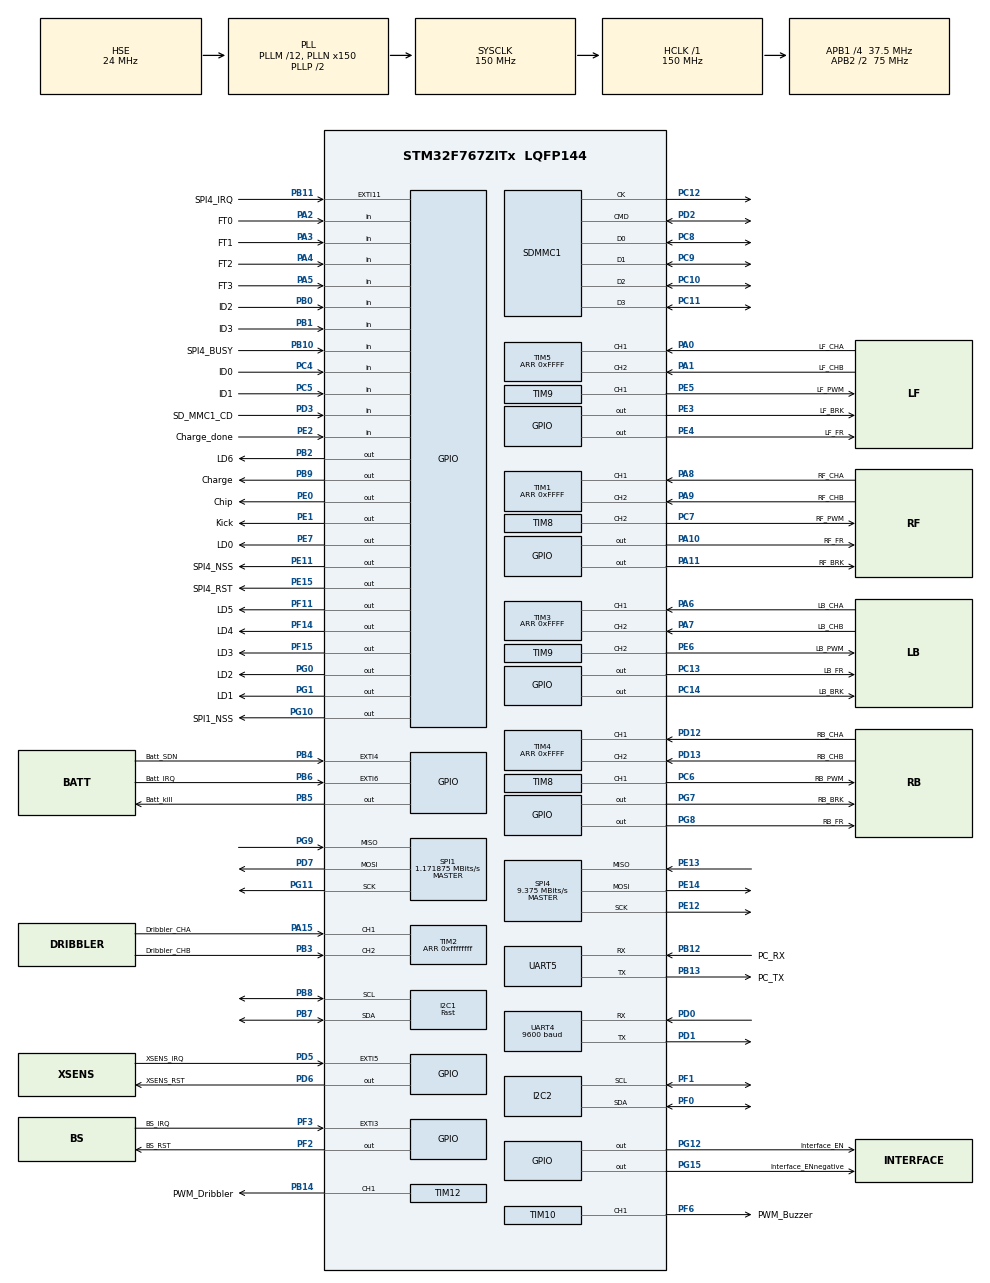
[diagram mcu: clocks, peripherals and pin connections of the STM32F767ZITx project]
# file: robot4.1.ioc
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CORTEX_M7.CPU_DCache=Enabled
CORTEX_M7.CPU_ICache=Enabled
CORTEX_M7.PREFETCH_ENABLE=1
Dma.I2C1_RX.5.Direction=DMA_PERIPH_TO_MEMORY
Dma.I2C1_RX.5.FIFOMode=DMA_FIFOMODE_DISABLE
Dma.I2C1_RX.5.Instance=DMA1_Stream0
Dma.I2C1_RX.5.MemDataAlignment=DMA_MDATAALIGN_BYTE
Dma.I2C1_RX.5.MemInc=DMA_MINC_ENABLE
Dma.I2C1_RX.5.Mode=DMA_NORMAL
Dma.I2C1_RX.5.PeriphDataAlignment=DMA_PDATAALIGN_BYTE
Dma.I2C1_RX.5.PeriphInc=DMA_PINC_DISABLE
Dma.I2C1_RX.5.Priority=DMA_PRIORITY_MEDIUM
Dma.Request0=SPI1_RX
Dma.Request1=SPI4_RX
Dma.Request2=UART5_TX
Dma.Request3=SPI4_TX
Dma.Request4=SPI1_TX
Dma.Request5=I2C1_RX
Dma.Request6=SDMMC1
Dma.SDMMC1.6.Direction=DMA_PERIPH_TO_MEMORY
Dma.SDMMC1.6.FIFOMode=DMA_FIFOMODE_ENABLE
Dma.SDMMC1.6.FIFOThreshold=DMA_FIFO_THRESHOLD_FULL
Dma.SDMMC1.6.Instance=DMA2_Stream6
Dma.SDMMC1.6.MemBurst=DMA_MBURST_INC4
Dma.SDMMC1.6.MemDataAlignment=DMA_MDATAALIGN_WORD
Dma.SDMMC1.6.MemInc=DMA_MINC_ENABLE
Dma.SDMMC1.6.Mode=DMA_PFCTRL
Dma.SDMMC1.6.PeriphBurst=DMA_PBURST_INC4
Dma.SDMMC1.6.PeriphDataAlignment=DMA_PDATAALIGN_WORD
Dma.SDMMC1.6.PeriphInc=DMA_PINC_DISABLE
Dma.SDMMC1.6.Priority=DMA_PRIORITY_LOW
Dma.SPI1_RX.0.Direction=DMA_PERIPH_TO_MEMORY
Dma.SPI1_RX.0.FIFOMode=DMA_FIFOMODE_DISABLE
Dma.SPI1_RX.0.Instance=DMA2_Stream0
Dma.SPI1_RX.0.MemDataAlignment=DMA_MDATAALIGN_BYTE
Dma.SPI1_RX.0.MemInc=DMA_MINC_ENABLE
Dma.SPI1_RX.0.Mode=DMA_NORMAL
Dma.SPI1_RX.0.PeriphDataAlignment=DMA_PDATAALIGN_BYTE
Dma.SPI1_RX.0.PeriphInc=DMA_PINC_DISABLE
Dma.SPI1_RX.0.Priority=DMA_PRIORITY_MEDIUM
Dma.SPI1_TX.4.Direction=DMA_MEMORY_TO_PERIPH
Dma.SPI1_TX.4.FIFOMode=DMA_FIFOMODE_DISABLE
Dma.SPI1_TX.4.Instance=DMA2_Stream5
Dma.SPI1_TX.4.MemDataAlignment=DMA_MDATAALIGN_BYTE
Dma.SPI1_TX.4.MemInc=DMA_MINC_ENABLE
Dma.SPI1_TX.4.Mode=DMA_NORMAL
Dma.SPI1_TX.4.PeriphDataAlignment=DMA_PDATAALIGN_BYTE
Dma.SPI1_TX.4.PeriphInc=DMA_PINC_DISABLE
Dma.SPI1_TX.4.Priority=DMA_PRIORITY_MEDIUM
Dma.SPI4_RX.1.Direction=DMA_PERIPH_TO_MEMORY
Dma.SPI4_RX.1.FIFOMode=DMA_FIFOMODE_DISABLE
Dma.SPI4_RX.1.Instance=DMA2_Stream3
Dma.SPI4_RX.1.MemDataAlignment=DMA_MDATAALIGN_BYTE
Dma.SPI4_RX.1.MemInc=DMA_MINC_ENABLE
Dma.SPI4_RX.1.Mode=DMA_NORMAL
Dma.SPI4_RX.1.PeriphDataAlignment=DMA_PDATAALIGN_BYTE
Dma.SPI4_RX.1.PeriphInc=DMA_PINC_DISABLE
Dma.SPI4_RX.1.Priority=DMA_PRIORITY_LOW
Dma.SPI4_TX.3.Direction=DMA_MEMORY_TO_PERIPH
Dma.SPI4_TX.3.FIFOMode=DMA_FIFOMODE_DISABLE
Dma.SPI4_TX.3.Instance=DMA2_Stream1
Dma.SPI4_TX.3.MemDataAlignment=DMA_MDATAALIGN_BYTE
Dma.SPI4_TX.3.MemInc=DMA_MINC_ENABLE
Dma.SPI4_TX.3.Mode=DMA_NORMAL
Dma.SPI4_TX.3.PeriphDataAlignment=DMA_PDATAALIGN_BYTE
Dma.SPI4_TX.3.PeriphInc=DMA_PINC_DISABLE
Dma.SPI4_TX.3.Priority=DMA_PRIORITY_LOW
Dma.UART5_TX.2.Direction=DMA_MEMORY_TO_PERIPH
Dma.UART5_TX.2.FIFOMode=DMA_FIFOMODE_DISABLE
Dma.UART5_TX.2.Instance=DMA1_Stream7
Dma.UART5_TX.2.MemDataAlignment=DMA_MDATAALIGN_BYTE
Dma.UART5_TX.2.MemInc=DMA_MINC_ENABLE
Dma.UART5_TX.2.Mode=DMA_NORMAL
Dma.UART5_TX.2.PeriphDataAlignment=DMA_PDATAALIGN_BYTE
Dma.UART5_TX.2.PeriphInc=DMA_PINC_DISABLE
Dma.UART5_TX.2.Priority=DMA_PRIORITY_LOW
FATFS.BSP.number=1
FATFS.USE_DMA_CODE_SD=1
FATFS0.BSP.STBoard=false
FATFS0.BSP.api=Unknown
FATFS0.BSP.instance=PD3
FATFS0.BSP.ip=GPIO
FATFS0.BSP.mode=Input
FATFS0.BSP.name=Detect_SDIO
FATFS0.BSP.solution=PD3
I2C1.I2C_Speed_Mode=I2C_Fast
I2C1.Timing=0x00301242
I2C2.Timing=0x00909FCE
Mcu.Family=STM32F7
Mcu.Name=STM32F767ZITx
Mcu.Package=LQFP144
Mcu.UserConstants=APB,150;ENCODER_FILTER,15;MAX_PWM,6000
NVIC.DMA1_Stream0_IRQn=true\:1\:0\:true\:false\:true\:false\:true\:true
NVIC.DMA1_Stream7_IRQn=true\:2\:0\:true\:false\:true\:false\:true\:true
NVIC.DMA2_Stream0_IRQn=true\:1\:0\:true\:false\:true\:false\:true\:true
NVIC.DMA2_Stream1_IRQn=true\:1\:0\:true\:false\:true\:false\:true\:true
NVIC.DMA2_Stream3_IRQn=true\:1\:0\:true\:false\:true\:false\:true\:true
NVIC.DMA2_Stream5_IRQn=true\:1\:0\:true\:false\:true\:false\:true\:true
NVIC.DMA2_Stream6_IRQn=true\:1\:0\:true\:false\:true\:false\:true\:true
NVIC.EXTI15_10_IRQn=true\:3\:0\:true\:false\:true\:true\:true\:true
NVIC.EXTI9_5_IRQn=true\:4\:0\:true\:false\:true\:true\:true\:true
NVIC.I2C1_EV_IRQn=true\:3\:0\:true\:false\:true\:true\:true\:true
NVIC.PriorityGroup=NVIC_PRIORITYGROUP_4
NVIC.SDMMC1_IRQn=true\:2\:0\:true\:false\:true\:true\:true\:true
NVIC.SPI1_IRQn=true\:2\:0\:true\:false\:true\:true\:true\:true
NVIC.SPI4_IRQn=true\:2\:0\:true\:false\:true\:true\:true\:true
NVIC.TIM1_TRG_COM_TIM11_IRQn=true\:2\:0\:true\:false\:true\:true\:true\:true
NVIC.TIM1_UP_TIM10_IRQn=true\:15\:0\:true\:false\:true\:true\:true\:true
NVIC.TIM6_DAC_IRQn=true\:5\:0\:true\:false\:true\:true\:true\:true
NVIC.TIM7_IRQn=true\:2\:0\:true\:false\:true\:true\:true\:true
NVIC.UART5_IRQn=true\:2\:0\:true\:false\:true\:true\:true\:true
PA0/WKUP.GPIO_Label=LF_CHA
PA0/WKUP.Signal=S_TIM5_CH1
PA1.GPIO_Label=LF_CHB
PA1.Signal=S_TIM5_CH2
PA10.GPIO_Label=RF_FR
PA10.Signal=GPIO_Output
PA11.GPIO_Label=RF_BRK
PA11.Signal=GPIO_Output
PA13.Mode=Serial_Wire
PA13.Signal=SYS_JTMS-SWDIO
PA14.Mode=Serial_Wire
PA14.Signal=SYS_JTCK-SWCLK
PA15.GPIO_Label=Dribbler_CHA
PA15.Signal=S_TIM2_CH1_ETR
PA2.GPIO_Label=FT0
PA2.Signal=GPIO_Input
PA3.GPIO_Label=FT1
PA3.Signal=GPIO_Input
PA4.GPIO_Label=FT2
PA4.Signal=GPIO_Input
PA5.GPIO_Label=FT3
PA5.Signal=GPIO_Input
PA6.GPIO_Label=LB_CHA
PA6.Signal=S_TIM3_CH1
PA7.GPIO_Label=LB_CHB
PA7.Signal=S_TIM3_CH2
PA8.GPIO_Label=RF_CHA
PA8.Signal=S_TIM1_CH1
PA9.GPIO_Label=RF_CHB
PA9.Signal=S_TIM1_CH2
PB0.GPIO_Label=ID2
PB0.Signal=GPIO_Input
PB1.GPIO_Label=ID3
PB1.Signal=GPIO_Input
PB10.GPIO_Label=SPI4_BUSY
PB10.Signal=GPIO_Input
PB11.GPIO_Label=SPI4_IRQ
PB11.Signal=GPXTI11
PB12.GPIO_Label=PC_RX
PB12.Mode=Asynchronous
PB12.Signal=UART5_RX
PB13.GPIO_Label=PC_TX
PB13.Mode=Asynchronous
PB13.Signal=UART5_TX
PB14.GPIO_Label=PWM_Dribbler
PB14.Signal=S_TIM12_CH1
PB2.GPIO_Label=LD6
PB2.Signal=GPIO_Output
PB3.GPIO_Label=Dribbler_CHB
PB3.Signal=S_TIM2_CH2
PB4.GPIO_Label=Batt_SDN
PB4.Signal=GPXTI4
PB5.GPIO_Label=Batt_kill
PB5.PinState=GPIO_PIN_SET
PB5.Signal=GPIO_Output
PB6.GPIO_Label=Batt_IRQ
PB6.Signal=GPXTI6
PB7.GPIO_FM7=SYSCFG_PMC_I2C_PB7_FMP
PB7.GPIO_Pu=GPIO_PULLUP
PB7.Mode=I2C
PB7.Signal=I2C1_SDA
PB8.GPIO_FM8=SYSCFG_PMC_I2C_PB8_FMP
PB8.GPIO_Pu=GPIO_PULLUP
PB8.Mode=I2C
PB8.Signal=I2C1_SCL
PB9.GPIO_Label=Charge
PB9.Signal=GPIO_Output
PC10.Mode=SD_4_bits_Wide_bus
PC10.Signal=SDMMC1_D2
PC11.Mode=SD_4_bits_Wide_bus
PC11.Signal=SDMMC1_D3
PC12.Mode=SD_4_bits_Wide_bus
PC12.Signal=SDMMC1_CK
PC13.GPIO_Label=LB_FR
PC13.Signal=GPIO_Output
PC14/OSC32_IN.GPIO_Label=LB_BRK
PC14/OSC32_IN.Signal=GPIO_Output
PC4.GPIO_Label=ID0
PC4.Signal=GPIO_Input
PC5.GPIO_Label=ID1
PC5.Signal=GPIO_Input
PC6.GPIO_Label=RB_PWM
PC6.GPIO_Speed=GPIO_SPEED_FREQ_HIGH
PC6.Signal=S_TIM8_CH1
PC7.GPIO_Label=RF_PWM
PC7.GPIO_Speed=GPIO_SPEED_FREQ_HIGH
PC7.Signal=S_TIM8_CH2
PC8.Mode=SD_4_bits_Wide_bus
PC8.Signal=SDMMC1_D0
PC9.Mode=SD_4_bits_Wide_bus
PC9.Signal=SDMMC1_D1
PD0.Mode=Asynchronous
PD0.Signal=UART4_RX
PD1.Mode=Asynchronous
PD1.Signal=UART4_TX
PD12.GPIO_Label=RB_CHA
PD12.Signal=S_TIM4_CH1
PD13.GPIO_Label=RB_CHB
PD13.Signal=S_TIM4_CH2
PD2.Mode=SD_4_bits_Wide_bus
PD2.Signal=SDMMC1_CMD
PD3.GPIO_Label=SD_MMC1_CD
PD3.Signal=GPIO_Input
PD5.GPIO_Label=XSENS_IRQ
PD5.Signal=GPXTI5
PD6.GPIO_Label=XSENS_RST
PD6.GPIO_ModeDefaultOutputPP=GPIO_MODE_OUTPUT_OD
PD6.PinState=GPIO_PIN_SET
PD6.Signal=GPIO_Output
PD7.Mode=Full_Duplex_Master
PD7.Signal=SPI1_MOSI
PE0.GPIO_Label=Chip
PE0.Signal=GPIO_Output
PE1.GPIO_Label=Kick
PE1.Signal=GPIO_Output
PE11.GPIO_Label=SPI4_NSS
PE11.Signal=GPIO_Output
PE12.Mode=Full_Duplex_Master
PE12.Signal=SPI4_SCK
PE13.Mode=Full_Duplex_Master
PE13.Signal=SPI4_MISO
PE14.Mode=Full_Duplex_Master
PE14.Signal=SPI4_MOSI
PE15.GPIO_Label=SPI4_RST
PE15.Signal=GPIO_Output
PE2.GPIO_Label=Charge_done
PE2.Signal=GPIO_Input
PE3.GPIO_Label=LF_BRK
PE3.Signal=GPIO_Output
PE4.GPIO_Label=LF_FR
PE4.Signal=GPIO_Output
PE5.GPIO_Label=LF_PWM
PE5.GPIO_Speed=GPIO_SPEED_FREQ_HIGH
PE5.Signal=S_TIM9_CH1
PE6.GPIO_Label=LB_PWM
PE6.GPIO_Speed=GPIO_SPEED_FREQ_HIGH
PE6.Signal=S_TIM9_CH2
PE7.GPIO_Label=LD0
PE7.Signal=GPIO_Output
PF0.Mode=I2C
PF0.Signal=I2C2_SDA
PF1.Mode=I2C
PF1.Signal=I2C2_SCL
PF11.GPIO_Label=LD5
PF11.Signal=GPIO_Output
PF14.GPIO_Label=LD4
PF14.Signal=GPIO_Output
PF15.GPIO_Label=LD3
PF15.Signal=GPIO_Output
PF2.GPIO_Label=BS_RST
PF2.PinState=GPIO_PIN_RESET
PF2.Signal=GPIO_Output
PF3.GPIO_Label=BS_IRQ
PF3.GPIO_ModeDefaultEXTI=GPIO_MODE_IT_RISING_FALLING
PF3.Signal=GPXTI3
PF6.GPIO_Label=PWM_Buzzer
PF6.GPIO_Speed=GPIO_SPEED_FREQ_HIGH
PF6.Signal=S_TIM10_CH1
PG0.GPIO_Label=LD2
PG0.Signal=GPIO_Output
PG1.GPIO_Label=LD1
PG1.Signal=GPIO_Output
PG10.GPIO_Label=SPI1_NSS
PG10.GPIO_Speed=GPIO_SPEED_FREQ_HIGH
PG10.Signal=GPIO_Output
PG11.Mode=Full_Duplex_Master
PG11.Signal=SPI1_SCK
PG12.GPIO_Label=Interface_EN
PG12.GPIO_Speed=GPIO_SPEED_FREQ_MEDIUM
PG12.Signal=GPIO_Output
PG15.GPIO_Label=Interface_ENnegative
PG15.GPIO_ModeDefaultOutputPP=GPIO_MODE_OUTPUT_PP
PG15.GPIO_PuPd=GPIO_NOPULL
PG15.GPIO_Speed=GPIO_SPEED_FREQ_MEDIUM
PG15.PinState=GPIO_PIN_SET
PG15.Signal=GPIO_Output
PG7.GPIO_Label=RB_BRK
PG7.Signal=GPIO_Output
PG8.GPIO_Label=RB_FR
PG8.Signal=GPIO_Output
PG9.Mode=Full_Duplex_Master
PG9.Signal=SPI1_MISO
PH0/OSC_IN.Mode=HSE-External-Clock-Source
PH0/OSC_IN.Signal=RCC_OSC_IN
PH1/OSC_OUT.Mode=HSE-External-Clock-Source
PH1/OSC_OUT.Signal=RCC_OSC_OUT
ProjectManager.HeapSize=0x200
ProjectManager.StackSize=0x400
ProjectManager.TargetToolchain=STM32CubeIDE
RCC.AHBFreq_Value=150000000
RCC.APB1CLKDivider=RCC_HCLK_DIV4
RCC.APB1Freq_Value=37500000
RCC.APB1TimFreq_Value=150000000
RCC.APB2CLKDivider=RCC_HCLK_DIV2
RCC.APB2Freq_Value=75000000
RCC.APB2TimFreq_Value=150000000
RCC.CortexFreq_Value=150000000
RCC.HCLKFreq_Value=150000000
RCC.HSE_VALUE=24000000
RCC.HSI_VALUE=16000000
RCC.LSE_VALUE=32768
RCC.PLLM=12
RCC.PLLN=150
RCC.PLLQ=6
RCC.PLLSourceVirtual=RCC_PLLSOURCE_HSE
RCC.RCC_TIM_PRescaler_Selection=RCC_TIMPRES_ACTIVATED
RCC.SDMMCClockSelection=RCC_SDMMC1CLKSOURCE_CLK48
RCC.SYSCLKFreq_VALUE=150000000
RCC.SYSCLKSource=RCC_SYSCLKSOURCE_PLLCLK
RCC.USBFreq_Value=50000000
RCC.VCOOutputFreq_Value=300000000
SH.S_TIM10_CH1.0=TIM10_CH1,PWM Generation1 CH1
SH.S_TIM12_CH1.0=TIM12_CH1,PWM Generation1 CH1
SH.S_TIM1_CH1.0=TIM1_CH1,Encoder_Interface
SH.S_TIM1_CH2.0=TIM1_CH2,Encoder_Interface
SH.S_TIM2_CH1_ETR.0=TIM2_CH1,Encoder_Interface
SH.S_TIM2_CH2.0=TIM2_CH2,Encoder_Interface
SH.S_TIM3_CH1.0=TIM3_CH1,Encoder_Interface
SH.S_TIM3_CH2.0=TIM3_CH2,Encoder_Interface
SH.S_TIM4_CH1.0=TIM4_CH1,Encoder_Interface
SH.S_TIM4_CH2.0=TIM4_CH2,Encoder_Interface
SH.S_TIM5_CH1.0=TIM5_CH1,Encoder_Interface
SH.S_TIM5_CH2.0=TIM5_CH2,Encoder_Interface
SH.S_TIM8_CH1.0=TIM8_CH1,PWM Generation1 CH1
SH.S_TIM8_CH2.0=TIM8_CH2,PWM Generation2 CH2
SH.S_TIM9_CH1.0=TIM9_CH1,PWM Generation1 CH1
SH.S_TIM9_CH2.0=TIM9_CH2,PWM Generation2 CH2
SPI1.BaudRatePrescaler=SPI_BAUDRATEPRESCALER_64
SPI1.CLKPhase=SPI_PHASE_2EDGE
SPI1.CLKPolarity=SPI_POLARITY_HIGH
SPI1.CalculateBaudRate=1.171875 MBits/s
SPI1.DataSize=SPI_DATASIZE_8BIT
SPI1.Direction=SPI_DIRECTION_2LINES
SPI1.Mode=SPI_MODE_MASTER
SPI1.VirtualNSS=VM_NSSHARD
SPI1.VirtualType=VM_MASTER
SPI4.BaudRatePrescaler=SPI_BAUDRATEPRESCALER_8
SPI4.CalculateBaudRate=9.375 MBits/s
SPI4.DataSize=SPI_DATASIZE_8BIT
SPI4.Direction=SPI_DIRECTION_2LINES
SPI4.Mode=SPI_MODE_MASTER
SPI4.VirtualType=VM_MASTER
TIM1.EncoderMode=TIM_ENCODERMODE_TI12
TIM1.Period=0xFFFF
TIM10.Channel=TIM_CHANNEL_1
TIM10.Period=MAX_PWM
TIM10.Prescaler=(APB-1)
TIM11.Period=0
TIM11.Prescaler=(APB*100)
TIM12.Channel-PWM\ Generation1\ CH1=TIM_CHANNEL_1
TIM12.Period=10000
TIM12.Prescaler=APB-1
TIM13.Prescaler=APB-1
TIM14.Prescaler=APB-1
TIM2.CounterMode=TIM_COUNTERMODE_DOWN
TIM2.EncoderMode=TIM_ENCODERMODE_TI12
TIM2.IC1Filter=ENCODER_FILTER
TIM2.IC1Polarity=TIM_ICPOLARITY_FALLING
TIM2.IC2Filter=ENCODER_FILTER
TIM2.Period=0xffffffff
TIM3.EncoderMode=TIM_ENCODERMODE_TI12
TIM3.IC1Filter=ENCODER_FILTER
TIM3.IC2Filter=ENCODER_FILTER
TIM3.Period=0xFFFF
TIM4.EncoderMode=TIM_ENCODERMODE_TI12
TIM4.IC1Filter=ENCODER_FILTER
TIM4.IC2Filter=ENCODER_FILTER
TIM4.Period=0xFFFF
TIM5.EncoderMode=TIM_ENCODERMODE_TI12
TIM5.IC1Filter=ENCODER_FILTER
TIM5.IC2Filter=ENCODER_FILTER
TIM5.Period=0xFFFF
TIM6.Period=50000
TIM6.Prescaler=(APB-1)
TIM7.Period=10000
TIM7.Prescaler=APB-1
TIM8.Channel-PWM\ Generation1\ CH1=TIM_CHANNEL_1
TIM8.Channel-PWM\ Generation2\ CH2=TIM_CHANNEL_2
TIM8.OCIdleState_1=TIM_OCIDLESTATE_SET
TIM8.OCIdleState_2=TIM_OCIDLESTATE_SET
TIM8.OCPolarity_1=TIM_OCPOLARITY_LOW
TIM8.OCPolarity_2=TIM_OCPOLARITY_LOW
TIM8.Period=MAX_PWM
TIM8.Prescaler=0
TIM9.Channel-PWM\ Generation1\ CH1=TIM_CHANNEL_1
TIM9.Channel-PWM\ Generation2\ CH2=TIM_CHANNEL_2
TIM9.OCPolarity_1=TIM_OCPOLARITY_LOW
TIM9.OCPolarity_2=TIM_OCPOLARITY_LOW
TIM9.Period=MAX_PWM
TIM9.Prescaler=0
UART4.BaudRate=9600
VP_FATFS_VS_SDIO.Mode=SDIO
VP_TIM10_VS_ClockSourceINT.Mode=Enable_Timer
VP_TIM11_VS_ClockSourceINT.Mode=Enable_Timer
VP_TIM12_VS_ClockSourceINT.Mode=Internal
VP_TIM13_VS_ClockSourceINT.Mode=Enable_Timer
VP_TIM14_VS_ClockSourceINT.Mode=Enable_Timer
VP_TIM6_VS_ClockSourceINT.Mode=Enable_Timer
VP_TIM7_VS_ClockSourceINT.Mode=Enable_Timer
board=custom

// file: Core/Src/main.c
/* USER CODE BEGIN Header */
/**
  ******************************************************************************
  * @file           : main.c
  * @brief          : Main program body
  ******************************************************************************
  ** This notice applies to any and all portions of this file
  * that are not between comment pairs USER CODE BEGIN and
  * USER CODE END. Other portions of this file, whether
  * inserted by the user or by software development tools
  * are owned by their respective copyright owners.
  *
  * COPYRIGHT(c) 2019 STMicroelectronics
  *
  * Redistribution and use in source and binary forms, with or without modification,
  * are permitted provided that the following conditions are met:
  *   1. Redistributions of source code must retain the above copyright notice,
  *      this list of conditions and the following disclaimer.
  *   2. Redistributions in binary form must reproduce the above copyright notice,
  *      this list of conditions and the following disclaimer in the documentation
  *      and/or other materials provided with the distribution.
  *   3. Neither the name of STMicroelectronics nor the names of its contributors
  *      may be used to endorse or promote products derived from this software
  *      without specific prior written permission.
  *
  * THIS SOFTWARE IS PROVIDED BY THE COPYRIGHT HOLDERS AND CONTRIBUTORS "AS IS"
  * AND ANY EXPRESS OR IMPLIED WARRANTIES, INCLUDING, BUT NOT LIMITED TO, THE
  * IMPLIED WARRANTIES OF MERCHANTABILITY AND FITNESS FOR A PARTICULAR PURPOSE ARE
  * DISCLAIMED. IN NO EVENT SHALL THE COPYRIGHT HOLDER OR CONTRIBUTORS BE LIABLE
  * FOR ANY DIRECT, INDIRECT, INCIDENTAL, SPECIAL, EXEMPLARY, OR CONSEQUENTIAL
  * DAMAGES (INCLUDING, BUT NOT LIMITED TO, PROCUREMENT OF SUBSTITUTE GOODS OR
  * SERVICES; LOSS OF USE, DATA, OR PROFITS; OR BUSINESS INTERRUPTION) HOWEVER
  * CAUSED AND ON ANY THEORY OF LIABILITY, WHETHER IN CONTRACT, STRICT LIABILITY,
  * OR TORT (INCLUDING NEGLIGENCE OR OTHERWISE) ARISING IN ANY WAY OUT OF THE USE
  * OF THIS SOFTWARE, EVEN IF ADVISED OF THE POSSIBILITY OF SUCH DAMAGE.
  *
  ******************************************************************************
  */
/* USER CODE END Header */
#include "main.h"
#include "fatfs.h"

/* USER CODE BEGIN Includes */
#include "robot.h"
/* USER CODE END Includes */

I2C_HandleTypeDef hi2c1;
I2C_HandleTypeDef hi2c2;
DMA_HandleTypeDef hdma_i2c1_rx;

SD_HandleTypeDef hsd1;
DMA_HandleTypeDef hdma_sdmmc1;

SPI_HandleTypeDef hspi1;
SPI_HandleTypeDef hspi4;
DMA_HandleTypeDef hdma_spi1_rx;
DMA_HandleTypeDef hdma_spi1_tx;
DMA_HandleTypeDef hdma_spi4_rx;
DMA_HandleTypeDef hdma_spi4_tx;

TIM_HandleTypeDef htim1;
TIM_HandleTypeDef htim2;
TIM_HandleTypeDef htim3;
TIM_HandleTypeDef htim4;
TIM_HandleTypeDef htim5;
TIM_HandleTypeDef htim6;
TIM_HandleTypeDef htim7;
TIM_HandleTypeDef htim8;
TIM_HandleTypeDef htim9;
TIM_HandleTypeDef htim10;
TIM_HandleTypeDef htim11;
TIM_HandleTypeDef htim12;
TIM_HandleTypeDef htim13;
TIM_HandleTypeDef htim14;

UART_HandleTypeDef huart4;
UART_HandleTypeDef huart5;
DMA_HandleTypeDef hdma_uart5_tx;

void SystemClock_Config(void);
void PeriphCommonClock_Config(void);
static void MX_GPIO_Init(void);
static void MX_DMA_Init(void);
static void MX_TIM2_Init(void);
static void MX_TIM3_Init(void);
static void MX_TIM4_Init(void);
static void MX_TIM6_Init(void);
static void MX_TIM7_Init(void);
static void MX_TIM8_Init(void);
static void MX_TIM10_Init(void);
static void MX_TIM1_Init(void);
static void MX_TIM9_Init(void);
static void MX_TIM5_Init(void);
static void MX_I2C1_Init(void);
static void MX_SPI4_Init(void);
static void MX_UART5_Init(void);
static void MX_SPI1_Init(void);
static void MX_TIM11_Init(void);
static void MX_TIM12_Init(void);
static void MX_TIM13_Init(void);
static void MX_TIM14_Init(void);
static void MX_I2C2_Init(void);
static void MX_SDMMC1_SD_Init(void);
static void MX_UART4_Init(void);

int main(void)
{

  /* Enable I-Cache---------------------------------------------------------*/
  SCB_EnableICache();

  /* Enable D-Cache---------------------------------------------------------*/
  SCB_EnableDCache();

  /* MCU Configuration--------------------------------------------------------*/

  /* Reset of all peripherals, Initializes the Flash interface and the Systick. */
  HAL_Init();

  /* Configure the system clock */
  SystemClock_Config();

/* Configure the peripherals common clocks */
  PeriphCommonClock_Config();

  /* USER CODE BEGIN SysInit */
  HAL_InitTick(0);
  /* USER CODE END SysInit */

  /* Initialize all configured peripherals */
  MX_GPIO_Init();
  MX_DMA_Init();
  MX_TIM2_Init();
  MX_TIM3_Init();
  MX_TIM4_Init();
  MX_TIM6_Init();
  MX_TIM7_Init();
  MX_TIM8_Init();
  MX_TIM10_Init();
  MX_TIM1_Init();
  MX_TIM9_Init();
  MX_TIM5_Init();
  MX_I2C1_Init();
  MX_SPI4_Init();
  MX_UART5_Init();
  MX_SPI1_Init();
  MX_TIM11_Init();
  MX_TIM12_Init();
  MX_TIM13_Init();
  MX_TIM14_Init();
  MX_I2C2_Init();
  MX_SDMMC1_SD_Init();
  MX_FATFS_Init();
  MX_UART4_Init();
  /* USER CODE BEGIN 2 */

  init();

  /* USER CODE END 2 */

  /* Infinite loop */
  /* USER CODE BEGIN WHILE */
  while (1)
  {

    loop();

    /* USER CODE END WHILE */

  }
}

void SystemClock_Config(void)
{
  RCC_OscInitTypeDef RCC_OscInitStruct = {0};
  RCC_ClkInitTypeDef RCC_ClkInitStruct = {0};

  /** Configure the main internal regulator output voltage
  */
  __HAL_RCC_PWR_CLK_ENABLE();
  __HAL_PWR_VOLTAGESCALING_CONFIG(PWR_REGULATOR_VOLTAGE_SCALE2);

  /** Initializes the RCC Oscillators according to the specified parameters
  * in the RCC_OscInitTypeDef structure.
  */
  RCC_OscInitStruct.OscillatorType = RCC_OSCILLATORTYPE_HSE;
  RCC_OscInitStruct.HSEState = RCC_HSE_BYPASS;
  RCC_OscInitStruct.PLL.PLLState = RCC_PLL_ON;
  RCC_OscInitStruct.PLL.PLLSource = RCC_PLLSOURCE_HSE;
  RCC_OscInitStruct.PLL.PLLM = 12;
  RCC_OscInitStruct.PLL.PLLN = 150;
  RCC_OscInitStruct.PLL.PLLP = RCC_PLLP_DIV2;
  RCC_OscInitStruct.PLL.PLLQ = 6;
  RCC_OscInitStruct.PLL.PLLR = 2;
  if (HAL_RCC_OscConfig(&RCC_OscInitStruct) != HAL_OK)
  {
    Error_Handler();
  }

  /** Initializes the CPU, AHB and APB buses clocks
  */
  RCC_ClkInitStruct.ClockType = RCC_CLOCKTYPE_HCLK|RCC_CLOCKTYPE_SYSCLK
                              |RCC_CLOCKTYPE_PCLK1|RCC_CLOCKTYPE_PCLK2;
  RCC_ClkInitStruct.SYSCLKSource = RCC_SYSCLKSOURCE_PLLCLK;
  RCC_ClkInitStruct.AHBCLKDivider = RCC_SYSCLK_DIV1;
  RCC_ClkInitStruct.APB1CLKDivider = RCC_HCLK_DIV4;
  RCC_ClkInitStruct.APB2CLKDivider = RCC_HCLK_DIV2;

  if (HAL_RCC_ClockConfig(&RCC_ClkInitStruct, FLASH_LATENCY_4) != HAL_OK)
  {
    Error_Handler();
  }
}

void PeriphCommonClock_Config(void)
{
  RCC_PeriphCLKInitTypeDef PeriphClkInitStruct = {0};

  /** Initializes the peripherals clock
  */
  PeriphClkInitStruct.PeriphClockSelection = RCC_PERIPHCLK_TIM;
  PeriphClkInitStruct.TIMPresSelection = RCC_TIMPRES_ACTIVATED;

  if (HAL_RCCEx_PeriphCLKConfig(&PeriphClkInitStruct) != HAL_OK)
  {
    Error_Handler();
  }
}

static void MX_I2C1_Init(void)
{

  hi2c1.Instance = I2C1;
  hi2c1.Init.Timing = 0x00301242;
  hi2c1.Init.OwnAddress1 = 0;
  hi2c1.Init.AddressingMode = I2C_ADDRESSINGMODE_7BIT;
  hi2c1.Init.DualAddressMode = I2C_DUALADDRESS_DISABLE;
  hi2c1.Init.OwnAddress2 = 0;
  hi2c1.Init.OwnAddress2Masks = I2C_OA2_NOMASK;
  hi2c1.Init.GeneralCallMode = I2C_GENERALCALL_DISABLE;
  hi2c1.Init.NoStretchMode = I2C_NOSTRETCH_DISABLE;
  if (HAL_I2C_Init(&hi2c1) != HAL_OK)
  {
    Error_Handler();
  }

  /** Configure Analogue filter
  */
  if (HAL_I2CEx_ConfigAnalogFilter(&hi2c1, I2C_ANALOGFILTER_ENABLE) != HAL_OK)
  {
    Error_Handler();
  }

  /** Configure Digital filter
  */
  if (HAL_I2CEx_ConfigDigitalFilter(&hi2c1, 0) != HAL_OK)
  {
    Error_Handler();
  }

}

static void MX_I2C2_Init(void)
{

  hi2c2.Instance = I2C2;
  hi2c2.Init.Timing = 0x00909FCE;
  hi2c2.Init.OwnAddress1 = 0;
  hi2c2.Init.AddressingMode = I2C_ADDRESSINGMODE_7BIT;
  hi2c2.Init.DualAddressMode = I2C_DUALADDRESS_DISABLE;
  hi2c2.Init.OwnAddress2 = 0;
  hi2c2.Init.OwnAddress2Masks = I2C_OA2_NOMASK;
  hi2c2.Init.GeneralCallMode = I2C_GENERALCALL_DISABLE;
  hi2c2.Init.NoStretchMode = I2C_NOSTRETCH_DISABLE;
  if (HAL_I2C_Init(&hi2c2) != HAL_OK)
  {
    Error_Handler();
  }

  /** Configure Analogue filter
  */
  if (HAL_I2CEx_ConfigAnalogFilter(&hi2c2, I2C_ANALOGFILTER_ENABLE) != HAL_OK)
  {
    Error_Handler();
  }

  /** Configure Digital filter
  */
  if (HAL_I2CEx_ConfigDigitalFilter(&hi2c2, 0) != HAL_OK)
  {
    Error_Handler();
  }

}

static void MX_SDMMC1_SD_Init(void)
{

  hsd1.Instance = SDMMC1;
  hsd1.Init.ClockEdge = SDMMC_CLOCK_EDGE_RISING;
  hsd1.Init.ClockBypass = SDMMC_CLOCK_BYPASS_DISABLE;
  hsd1.Init.ClockPowerSave = SDMMC_CLOCK_POWER_SAVE_DISABLE;
  hsd1.Init.BusWide = SDMMC_BUS_WIDE_1B;
  hsd1.Init.HardwareFlowControl = SDMMC_HARDWARE_FLOW_CONTROL_DISABLE;
  hsd1.Init.ClockDiv = 0;

}

static void MX_SPI1_Init(void)
{

  /* SPI1 parameter configuration*/
  hspi1.Instance = SPI1;
  hspi1.Init.Mode = SPI_MODE_MASTER;
  hspi1.Init.Direction = SPI_DIRECTION_2LINES;
  hspi1.Init.DataSize = SPI_DATASIZE_8BIT;
  hspi1.Init.CLKPolarity = SPI_POLARITY_HIGH;
  hspi1.Init.CLKPhase = SPI_PHASE_2EDGE;
  hspi1.Init.NSS = SPI_NSS_SOFT;
  hspi1.Init.BaudRatePrescaler = SPI_BAUDRATEPRESCALER_64;
  hspi1.Init.FirstBit = SPI_FIRSTBIT_MSB;
  hspi1.Init.TIMode = SPI_TIMODE_DISABLE;
  hspi1.Init.CRCCalculation = SPI_CRCCALCULATION_DISABLE;
  hspi1.Init.CRCPolynomial = 7;
  hspi1.Init.CRCLength = SPI_CRC_LENGTH_DATASIZE;
  hspi1.Init.NSSPMode = SPI_NSS_PULSE_DISABLE;
  if (HAL_SPI_Init(&hspi1) != HAL_OK)
  {
    Error_Handler();
  }

}

static void MX_SPI4_Init(void)
{

  /* SPI4 parameter configuration*/
  hspi4.Instance = SPI4;
  hspi4.Init.Mode = SPI_MODE_MASTER;
  hspi4.Init.Direction = SPI_DIRECTION_2LINES;
  hspi4.Init.DataSize = SPI_DATASIZE_8BIT;
  hspi4.Init.CLKPolarity = SPI_POLARITY_LOW;
  hspi4.Init.CLKPhase = SPI_PHASE_1EDGE;
  hspi4.Init.NSS = SPI_NSS_SOFT;
  hspi4.Init.BaudRatePrescaler = SPI_BAUDRATEPRESCALER_8;
  hspi4.Init.FirstBit = SPI_FIRSTBIT_MSB;
  hspi4.Init.TIMode = SPI_TIMODE_DISABLE;
  hspi4.Init.CRCCalculation = SPI_CRCCALCULATION_DISABLE;
  hspi4.Init.CRCPolynomial = 7;
  hspi4.Init.CRCLength = SPI_CRC_LENGTH_DATASIZE;
  hspi4.Init.NSSPMode = SPI_NSS_PULSE_ENABLE;
  if (HAL_SPI_Init(&hspi4) != HAL_OK)
  {
    Error_Handler();
  }

}

static void MX_TIM1_Init(void)
{

  TIM_Encoder_InitTypeDef sConfig = {0};
  TIM_MasterConfigTypeDef sMasterConfig = {0};

  htim1.Instance = TIM1;
  htim1.Init.Prescaler = 0;
  htim1.Init.CounterMode = TIM_COUNTERMODE_UP;
  htim1.Init.Period = 0xFFFF;
  htim1.Init.ClockDivision = TIM_CLOCKDIVISION_DIV1;
  htim1.Init.RepetitionCounter = 0;
  htim1.Init.AutoReloadPreload = TIM_AUTORELOAD_PRELOAD_DISABLE;
  sConfig.EncoderMode = TIM_ENCODERMODE_TI12;
  sConfig.IC1Polarity = TIM_ICPOLARITY_RISING;
  sConfig.IC1Selection = TIM_ICSELECTION_DIRECTTI;
  sConfig.IC1Prescaler = TIM_ICPSC_DIV1;
  sConfig.IC1Filter = 0;
  sConfig.IC2Polarity = TIM_ICPOLARITY_RISING;
  sConfig.IC2Selection = TIM_ICSELECTION_DIRECTTI;
  sConfig.IC2Prescaler = TIM_ICPSC_DIV1;
  sConfig.IC2Filter = 0;
  if (HAL_TIM_Encoder_Init(&htim1, &sConfig) != HAL_OK)
  {
    Error_Handler();
  }
  sMasterConfig.MasterOutputTrigger = TIM_TRGO_RESET;
  sMasterConfig.MasterOutputTrigger2 = TIM_TRGO2_RESET;
  sMasterConfig.MasterSlaveMode = TIM_MASTERSLAVEMODE_DISABLE;
  if (HAL_TIMEx_MasterConfigSynchronization(&htim1, &sMasterConfig) != HAL_OK)
  {
    Error_Handler();
  }

}

static void MX_TIM2_Init(void)
{

  TIM_Encoder_InitTypeDef sConfig = {0};
  TIM_MasterConfigTypeDef sMasterConfig = {0};

  htim2.Instance = TIM2;
  htim2.Init.Prescaler = 0;
  htim2.Init.CounterMode = TIM_COUNTERMODE_DOWN;
  htim2.Init.Period = 0xffffffff;
  htim2.Init.ClockDivision = TIM_CLOCKDIVISION_DIV1;
  htim2.Init.AutoReloadPreload = TIM_AUTORELOAD_PRELOAD_DISABLE;
  sConfig.EncoderMode = TIM_ENCODERMODE_TI12;
  sConfig.IC1Polarity = TIM_ICPOLARITY_FALLING;
  sConfig.IC1Selection = TIM_ICSELECTION_DIRECTTI;
  sConfig.IC1Prescaler = TIM_ICPSC_DIV1;
  sConfig.IC1Filter = ENCODER_FILTER;
  sConfig.IC2Polarity = TIM_ICPOLARITY_RISING;
  sConfig.IC2Selection = TIM_ICSELECTION_DIRECTTI;
  sConfig.IC2Prescaler = TIM_ICPSC_DIV1;
  sConfig.IC2Filter = ENCODER_FILTER;
  if (HAL_TIM_Encoder_Init(&htim2, &sConfig) != HAL_OK)
  {
    Error_Handler();
  }
  sMasterConfig.MasterOutputTrigger = TIM_TRGO_RESET;
  sMasterConfig.MasterSlaveMode = TIM_MASTERSLAVEMODE_DISABLE;
  if (HAL_TIMEx_MasterConfigSynchronization(&htim2, &sMasterConfig) != HAL_OK)
  {
    Error_Handler();
  }

}

static void MX_TIM3_Init(void)
{

  TIM_Encoder_InitTypeDef sConfig = {0};
  TIM_MasterConfigTypeDef sMasterConfig = {0};

  htim3.Instance = TIM3;
  htim3.Init.Prescaler = 0;
  htim3.Init.CounterMode = TIM_COUNTERMODE_UP;
  htim3.Init.Period = 0xFFFF;
  htim3.Init.ClockDivision = TIM_CLOCKDIVISION_DIV1;
  htim3.Init.AutoReloadPreload = TIM_AUTORELOAD_PRELOAD_DISABLE;
  sConfig.EncoderMode = TIM_ENCODERMODE_TI12;
  sConfig.IC1Polarity = TIM_ICPOLARITY_RISING;
  sConfig.IC1Selection = TIM_ICSELECTION_DIRECTTI;
  sConfig.IC1Prescaler = TIM_ICPSC_DIV1;
  sConfig.IC1Filter = ENCODER_FILTER;
  sConfig.IC2Polarity = TIM_ICPOLARITY_RISING;
  sConfig.IC2Selection = TIM_ICSELECTION_DIRECTTI;
  sConfig.IC2Prescaler = TIM_ICPSC_DIV1;
  sConfig.IC2Filter = ENCODER_FILTER;
  if (HAL_TIM_Encoder_Init(&htim3, &sConfig) != HAL_OK)
  {
    Error_Handler();
  }
  sMasterConfig.MasterOutputTrigger = TIM_TRGO_RESET;
  sMasterConfig.MasterSlaveMode = TIM_MASTERSLAVEMODE_DISABLE;
  if (HAL_TIMEx_MasterConfigSynchronization(&htim3, &sMasterConfig) != HAL_OK)
  {
    Error_Handler();
  }

}

static void MX_TIM4_Init(void)
{

  TIM_Encoder_InitTypeDef sConfig = {0};
  TIM_MasterConfigTypeDef sMasterConfig = {0};

  htim4.Instance = TIM4;
  htim4.Init.Prescaler = 0;
  htim4.Init.CounterMode = TIM_COUNTERMODE_UP;
  htim4.Init.Period = 0xFFFF;
  htim4.Init.ClockDivision = TIM_CLOCKDIVISION_DIV1;
  htim4.Init.AutoReloadPreload = TIM_AUTORELOAD_PRELOAD_DISABLE;
  sConfig.EncoderMode = TIM_ENCODERMODE_TI12;
  sConfig.IC1Polarity = TIM_ICPOLARITY_RISING;
  sConfig.IC1Selection = TIM_ICSELECTION_DIRECTTI;
  sConfig.IC1Prescaler = TIM_ICPSC_DIV1;
  sConfig.IC1Filter = ENCODER_FILTER;
  sConfig.IC2Polarity = TIM_ICPOLARITY_RISING;
  sConfig.IC2Selection = TIM_ICSELECTION_DIRECTTI;
  sConfig.IC2Prescaler = TIM_ICPSC_DIV1;
  sConfig.IC2Filter = ENCODER_FILTER;
  if (HAL_TIM_Encoder_Init(&htim4, &sConfig) != HAL_OK)
  {
    Error_Handler();
  }
  sMasterConfig.MasterOutputTrigger = TIM_TRGO_RESET;
  sMasterConfig.MasterSlaveMode = TIM_MASTERSLAVEMODE_DISABLE;
  if (HAL_TIMEx_MasterConfigSynchronization(&htim4, &sMasterConfig) != HAL_OK)
  {
    Error_Handler();
  }

}

static void MX_TIM5_Init(void)
{

  TIM_Encoder_InitTypeDef sConfig = {0};
  TIM_MasterConfigTypeDef sMasterConfig = {0};

  htim5.Instance = TIM5;
  htim5.Init.Prescaler = 0;
  htim5.Init.CounterMode = TIM_COUNTERMODE_UP;
  htim5.Init.Period = 0xFFFF;
  htim5.Init.ClockDivision = TIM_CLOCKDIVISION_DIV1;
  htim5.Init.AutoReloadPreload = TIM_AUTORELOAD_PRELOAD_DISABLE;
  sConfig.EncoderMode = TIM_ENCODERMODE_TI12;
  sConfig.IC1Polarity = TIM_ICPOLARITY_RISING;
  sConfig.IC1Selection = TIM_ICSELECTION_DIRECTTI;
  sConfig.IC1Prescaler = TIM_ICPSC_DIV1;
  sConfig.IC1Filter = ENCODER_FILTER;
  sConfig.IC2Polarity = TIM_ICPOLARITY_RISING;
  sConfig.IC2Selection = TIM_ICSELECTION_DIRECTTI;
  sConfig.IC2Prescaler = TIM_ICPSC_DIV1;
  sConfig.IC2Filter = ENCODER_FILTER;
  if (HAL_TIM_Encoder_Init(&htim5, &sConfig) != HAL_OK)
  {
    Error_Handler();
  }
  sMasterConfig.MasterOutputTrigger = TIM_TRGO_RESET;
  sMasterConfig.MasterSlaveMode = TIM_MASTERSLAVEMODE_DISABLE;
  if (HAL_TIMEx_MasterConfigSynchronization(&htim5, &sMasterConfig) != HAL_OK)
  {
    Error_Handler();
  }

}

static void MX_TIM6_Init(void)
{

  TIM_MasterConfigTypeDef sMasterConfig = {0};

  htim6.Instance = TIM6;
  htim6.Init.Prescaler = (APB-1);
  htim6.Init.CounterMode = TIM_COUNTERMODE_UP;
  htim6.Init.Period = 50000;
  htim6.Init.AutoReloadPreload = TIM_AUTORELOAD_PRELOAD_DISABLE;
  if (HAL_TIM_Base_Init(&htim6) != HAL_OK)
  {
    Error_Handler();
  }
  sMasterConfig.MasterOutputTrigger = TIM_TRGO_RESET;
  sMasterConfig.MasterSlaveMode = TIM_MASTERSLAVEMODE_DISABLE;
  if (HAL_TIMEx_MasterConfigSynchronization(&htim6, &sMasterConfig) != HAL_OK)
  {
    Error_Handler();
  }

}

static void MX_TIM7_Init(void)
{

  TIM_MasterConfigTypeDef sMasterConfig = {0};

  htim7.Instance = TIM7;
  htim7.Init.Prescaler = APB-1;
  htim7.Init.CounterMode = TIM_COUNTERMODE_UP;
  htim7.Init.Period = 10000;
  htim7.Init.AutoReloadPreload = TIM_AUTORELOAD_PRELOAD_DISABLE;
  if (HAL_TIM_Base_Init(&htim7) != HAL_OK)
  {
    Error_Handler();
  }
  sMasterConfig.MasterOutputTrigger = TIM_TRGO_RESET;
  sMasterConfig.MasterSlaveMode = TIM_MASTERSLAVEMODE_DISABLE;
  if (HAL_TIMEx_MasterConfigSynchronization(&htim7, &sMasterConfig) != HAL_OK)
  {
    Error_Handler();
  }

}

static void MX_TIM8_Init(void)
{

  TIM_MasterConfigTypeDef sMasterConfig = {0};
  TIM_OC_InitTypeDef sConfigOC = {0};
  TIM_BreakDeadTimeConfigTypeDef sBreakDeadTimeConfig = {0};

  htim8.Instance = TIM8;
  htim8.Init.Prescaler = 0;
  htim8.Init.CounterMode = TIM_COUNTERMODE_UP;
  htim8.Init.Period = MAX_PWM;
  htim8.Init.ClockDivision = TIM_CLOCKDIVISION_DIV1;
  htim8.Init.RepetitionCounter = 0;
  htim8.Init.AutoReloadPreload = TIM_AUTORELOAD_PRELOAD_DISABLE;
  if (HAL_TIM_PWM_Init(&htim8) != HAL_OK)
  {
    Error_Handler();
  }
  sMasterConfig.MasterOutputTrigger = TIM_TRGO_RESET;
  sMasterConfig.MasterOutputTrigger2 = TIM_TRGO2_RESET;
  sMasterConfig.MasterSlaveMode = TIM_MASTERSLAVEMODE_DISABLE;
  if (HAL_TIMEx_MasterConfigSynchronization(&htim8, &sMasterConfig) != HAL_OK)
  {
    Error_Handler();
  }
  sConfigOC.OCMode = TIM_OCMODE_PWM1;
  sConfigOC.Pulse = 0;
  sConfigOC.OCPolarity = TIM_OCPOLARITY_LOW;
  sConfigOC.OCNPolarity = TIM_OCNPOLARITY_HIGH;
  sConfigOC.OCFastMode = TIM_OCFAST_DISABLE;
  sConfigOC.OCIdleState = TIM_OCIDLESTATE_SET;
  sConfigOC.OCNIdleState = TIM_OCNIDLESTATE_RESET;
  if (HAL_TIM_PWM_ConfigChannel(&htim8, &sConfigOC, TIM_CHANNEL_1) != HAL_OK)
  {
    Error_Handler();
  }
  if (HAL_TIM_PWM_ConfigChannel(&htim8, &sConfigOC, TIM_CHANNEL_2) != HAL_OK)
  {
    Error_Handler();
  }
  sBreakDeadTimeConfig.OffStateRunMode = TIM_OSSR_DISABLE;
  sBreakDeadTimeConfig.OffStateIDLEMode = TIM_OSSI_DISABLE;
  sBreakDeadTimeConfig.LockLevel = TIM_LOCKLEVEL_OFF;
  sBreakDeadTimeConfig.DeadTime = 0;
  sBreakDeadTimeConfig.BreakState = TIM_BREAK_DISABLE;
  sBreakDeadTimeConfig.BreakPolarity = TIM_BREAKPOLARITY_HIGH;
  sBreakDeadTimeConfig.BreakFilter = 0;
  sBreakDeadTimeConfig.Break2State = TIM_BREAK2_DISABLE;
  sBreakDeadTimeConfig.Break2Polarity = TIM_BREAK2POLARITY_HIGH;
  sBreakDeadTimeConfig.Break2Filter = 0;
  sBreakDeadTimeConfig.AutomaticOutput = TIM_AUTOMATICOUTPUT_DISABLE;
  if (HAL_TIMEx_ConfigBreakDeadTime(&htim8, &sBreakDeadTimeConfig) != HAL_OK)
  {
    Error_Handler();
  }
  HAL_TIM_MspPostInit(&htim8);

}

static void MX_TIM9_Init(void)
{

  TIM_OC_InitTypeDef sConfigOC = {0};

  htim9.Instance = TIM9;
  htim9.Init.Prescaler = 0;
  htim9.Init.CounterMode = TIM_COUNTERMODE_UP;
  htim9.Init.Period = MAX_PWM;
  htim9.Init.ClockDivision = TIM_CLOCKDIVISION_DIV1;
  htim9.Init.AutoReloadPreload = TIM_AUTORELOAD_PRELOAD_DISABLE;
  if (HAL_TIM_PWM_Init(&htim9) != HAL_OK)
  {
    Error_Handler();
  }
  sConfigOC.OCMode = TIM_OCMODE_PWM1;
  sConfigOC.Pulse = 0;
  sConfigOC.OCPolarity = TIM_OCPOLARITY_LOW;
  sConfigOC.OCFastMode = TIM_OCFAST_DISABLE;
  if (HAL_TIM_PWM_ConfigChannel(&htim9, &sConfigOC, TIM_CHANNEL_1) != HAL_OK)
  {
    Error_Handler();
  }
  if (HAL_TIM_PWM_ConfigChannel(&htim9, &sConfigOC, TIM_CHANNEL_2) != HAL_OK)
  {
    Error_Handler();
  }
  HAL_TIM_MspPostInit(&htim9);

}

static void MX_TIM10_Init(void)
{

  TIM_OC_InitTypeDef sConfigOC = {0};

  htim10.Instance = TIM10;
  htim10.Init.Prescaler = (APB-1);
  htim10.Init.CounterMode = TIM_COUNTERMODE_UP;
  htim10.Init.Period = MAX_PWM;
  htim10.Init.ClockDivision = TIM_CLOCKDIVISION_DIV1;
  htim10.Init.AutoReloadPreload = TIM_AUTORELOAD_PRELOAD_DISABLE;
  if (HAL_TIM_Base_Init(&htim10) != HAL_OK)
  {
    Error_Handler();
  }
  if (HAL_TIM_PWM_Init(&htim10) != HAL_OK)
  {
    Error_Handler();
  }
  sConfigOC.OCMode = TIM_OCMODE_PWM1;
  sConfigOC.Pulse = 0;
  sConfigOC.OCPolarity = TIM_OCPOLARITY_HIGH;
  sConfigOC.OCFastMode = TIM_OCFAST_DISABLE;
  if (HAL_TIM_PWM_ConfigChannel(&htim10, &sConfigOC, TIM_CHANNEL_1) != HAL_OK)
  {
    Error_Handler();
  }
  HAL_TIM_MspPostInit(&htim10);

}

static void MX_TIM11_Init(void)
{

  htim11.Instance = TIM11;
  htim11.Init.Prescaler = (APB*100);
  htim11.Init.CounterMode = TIM_COUNTERMODE_UP;
  htim11.Init.Period = 0;
  htim11.Init.ClockDivision = TIM_CLOCKDIVISION_DIV1;
  htim11.Init.AutoReloadPreload = TIM_AUTORELOAD_PRELOAD_DISABLE;
  if (HAL_TIM_Base_Init(&htim11) != HAL_OK)
  {
    Error_Handler();
  }

}

static void MX_TIM12_Init(void)
{

  TIM_ClockConfigTypeDef sClockSourceConfig = {0};
  TIM_OC_InitTypeDef sConfigOC = {0};

  htim12.Instance = TIM12;
  htim12.Init.Prescaler = APB-1;
  htim12.Init.CounterMode = TIM_COUNTERMODE_UP;
  htim12.Init.Period = 10000;
  htim12.Init.ClockDivision = TIM_CLOCKDIVISION_DIV1;
  htim12.Init.AutoReloadPreload = TIM_AUTORELOAD_PRELOAD_DISABLE;
  if (HAL_TIM_Base_Init(&htim12) != HAL_OK)
  {
    Error_Handler();
  }
  sClockSourceConfig.ClockSource = TIM_CLOCKSOURCE_INTERNAL;
  if (HAL_TIM_ConfigClockSource(&htim12, &sClockSourceConfig) != HAL_OK)
  {
    Error_Handler();
  }
  if (HAL_TIM_PWM_Init(&htim12) != HAL_OK)
  {
    Error_Handler();
  }
  sConfigOC.OCMode = TIM_OCMODE_PWM1;
  sConfigOC.Pulse = 0;
  sConfigOC.OCPolarity = TIM_OCPOLARITY_HIGH;
  sConfigOC.OCFastMode = TIM_OCFAST_DISABLE;
  if (HAL_TIM_PWM_ConfigChannel(&htim12, &sConfigOC, TIM_CHANNEL_1) != HAL_OK)
  {
    Error_Handler();
  }
  HAL_TIM_MspPostInit(&htim12);

}

static void MX_TIM13_Init(void)
{

  htim13.Instance = TIM13;
  htim13.Init.Prescaler = APB-1;
  htim13.Init.CounterMode = TIM_COUNTERMODE_UP;
  htim13.Init.Period = 65535;
  htim13.Init.ClockDivision = TIM_CLOCKDIVISION_DIV1;
  htim13.Init.AutoReloadPreload = TIM_AUTORELOAD_PRELOAD_DISABLE;
  if (HAL_TIM_Base_Init(&htim13) != HAL_OK)
  {
    Error_Handler();
  }

}

static void MX_TIM14_Init(void)
{

  htim14.Instance = TIM14;
  htim14.Init.Prescaler = APB-1;
  htim14.Init.CounterMode = TIM_COUNTERMODE_UP;
  htim14.Init.Period = 65535;
  htim14.Init.ClockDivision = TIM_CLOCKDIVISION_DIV1;
  htim14.Init.AutoReloadPreload = TIM_AUTORELOAD_PRELOAD_DISABLE;
  if (HAL_TIM_Base_Init(&htim14) != HAL_OK)
  {
    Error_Handler();
  }

}

static void MX_UART4_Init(void)
{

  huart4.Instance = UART4;
  huart4.Init.BaudRate = 9600;
  huart4.Init.WordLength = UART_WORDLENGTH_8B;
  huart4.Init.StopBits = UART_STOPBITS_1;
  huart4.Init.Parity = UART_PARITY_NONE;
  huart4.Init.Mode = UART_MODE_TX_RX;
  huart4.Init.HwFlowCtl = UART_HWCONTROL_NONE;
  huart4.Init.OverSampling = UART_OVERSAMPLING_16;
  huart4.Init.OneBitSampling = UART_ONE_BIT_SAMPLE_DISABLE;
  huart4.AdvancedInit.AdvFeatureInit = UART_ADVFEATURE_NO_INIT;
  if (HAL_UART_Init(&huart4) != HAL_OK)
  {
    Error_Handler();
  }

}

static void MX_UART5_Init(void)
{

  huart5.Instance = UART5;
  huart5.Init.BaudRate = 115200;
  huart5.Init.WordLength = UART_WORDLENGTH_8B;
  huart5.Init.StopBits = UART_STOPBITS_1;
  huart5.Init.Parity = UART_PARITY_NONE;
  huart5.Init.Mode = UART_MODE_TX_RX;
  huart5.Init.HwFlowCtl = UART_HWCONTROL_NONE;
  huart5.Init.OverSampling = UART_OVERSAMPLING_16;
  huart5.Init.OneBitSampling = UART_ONE_BIT_SAMPLE_DISABLE;
  huart5.AdvancedInit.AdvFeatureInit = UART_ADVFEATURE_NO_INIT;
  if (HAL_UART_Init(&huart5) != HAL_OK)
  {
    Error_Handler();
  }

}

static void MX_DMA_Init(void)
{

  /* DMA controller clock enable */
  __HAL_RCC_DMA2_CLK_ENABLE();
  __HAL_RCC_DMA1_CLK_ENABLE();

  /* DMA interrupt init */
  /* DMA1_Stream0_IRQn interrupt configuration */
  HAL_NVIC_SetPriority(DMA1_Stream0_IRQn, 1, 0);
  HAL_NVIC_EnableIRQ(DMA1_Stream0_IRQn);
  /* DMA1_Stream7_IRQn interrupt configuration */
  HAL_NVIC_SetPriority(DMA1_Stream7_IRQn, 2, 0);
  HAL_NVIC_EnableIRQ(DMA1_Stream7_IRQn);
  /* DMA2_Stream0_IRQn interrupt configuration */
  HAL_NVIC_SetPriority(DMA2_Stream0_IRQn, 1, 0);
  HAL_NVIC_EnableIRQ(DMA2_Stream0_IRQn);
  /* DMA2_Stream1_IRQn interrupt configuration */
  HAL_NVIC_SetPriority(DMA2_Stream1_IRQn, 1, 0);
  HAL_NVIC_EnableIRQ(DMA2_Stream1_IRQn);
  /* DMA2_Stream3_IRQn interrupt configuration */
  HAL_NVIC_SetPriority(DMA2_Stream3_IRQn, 1, 0);
  HAL_NVIC_EnableIRQ(DMA2_Stream3_IRQn);
  /* DMA2_Stream5_IRQn interrupt configuration */
  HAL_NVIC_SetPriority(DMA2_Stream5_IRQn, 1, 0);
  HAL_NVIC_EnableIRQ(DMA2_Stream5_IRQn);
  /* DMA2_Stream6_IRQn interrupt configuration */
  HAL_NVIC_SetPriority(DMA2_Stream6_IRQn, 1, 0);
  HAL_NVIC_EnableIRQ(DMA2_Stream6_IRQn);

}

static void MX_GPIO_Init(void)
{
  GPIO_InitTypeDef GPIO_InitStruct = {0};

  /* GPIO Ports Clock Enable */
  __HAL_RCC_GPIOE_CLK_ENABLE();
  __HAL_RCC_GPIOC_CLK_ENABLE();
  __HAL_RCC_GPIOF_CLK_ENABLE();
  __HAL_RCC_GPIOH_CLK_ENABLE();
  __HAL_RCC_GPIOA_CLK_ENABLE();
  __HAL_RCC_GPIOB_CLK_ENABLE();
  __HAL_RCC_GPIOG_CLK_ENABLE();
  __HAL_RCC_GPIOD_CLK_ENABLE();

  /*Configure GPIO pin Output Level */
  HAL_GPIO_WritePin(GPIOE, LF_BRK_Pin|LF_FR_Pin|LD0_Pin|SPI4_NSS_Pin
                          |SPI4_RST_Pin|Chip_Pin|Kick_Pin, GPIO_PIN_RESET);

  /*Configure GPIO pin Output Level */
  HAL_GPIO_WritePin(GPIOC, LB_FR_Pin|LB_BRK_Pin, GPIO_PIN_RESET);

  /*Configure GPIO pin Output Level */
  HAL_GPIO_WritePin(GPIOF, BS_RST_Pin|LD5_Pin|LD4_Pin|LD3_Pin, GPIO_PIN_RESET);

  /*Configure GPIO pin Output Level */
  HAL_GPIO_WritePin(GPIOB, LD6_Pin|Charge_Pin, GPIO_PIN_RESET);

  /*Configure GPIO pin Output Level */
  HAL_GPIO_WritePin(GPIOG, LD2_Pin|LD1_Pin|RB_BRK_Pin|RB_FR_Pin
                          |SPI1_NSS_Pin|Interface_EN_Pin, GPIO_PIN_RESET);

  /*Configure GPIO pin Output Level */
  HAL_GPIO_WritePin(GPIOA, RF_FR_Pin|RF_BRK_Pin, GPIO_PIN_RESET);

  /*Configure GPIO pin Output Level */
  HAL_GPIO_WritePin(XSENS_RST_GPIO_Port, XSENS_RST_Pin, GPIO_PIN_SET);

  /*Configure GPIO pin Output Level */
  HAL_GPIO_WritePin(Interface_ENnegative_GPIO_Port, Interface_ENnegative_Pin, GPIO_PIN_SET);

  /*Configure GPIO pin Output Level */
  HAL_GPIO_WritePin(Batt_kill_GPIO_Port, Batt_kill_Pin, GPIO_PIN_SET);

  /*Configure GPIO pin : Charge_done_Pin */
  GPIO_InitStruct.Pin = Charge_done_Pin;
  GPIO_InitStruct.Mode = GPIO_MODE_INPUT;
  GPIO_InitStruct.Pull = GPIO_NOPULL;
  HAL_GPIO_Init(Charge_done_GPIO_Port, &GPIO_InitStruct);

  /*Configure GPIO pins : LF_BRK_Pin LF_FR_Pin LD0_Pin SPI4_NSS_Pin
                           SPI4_RST_Pin Chip_Pin Kick_Pin */
  GPIO_InitStruct.Pin = LF_BRK_Pin|LF_FR_Pin|LD0_Pin|SPI4_NSS_Pin
                          |SPI4_RST_Pin|Chip_Pin|Kick_Pin;
  GPIO_InitStruct.Mode = GPIO_MODE_OUTPUT_PP;
  GPIO_InitStruct.Pull = GPIO_NOPULL;
  GPIO_InitStruct.Speed = GPIO_SPEED_FREQ_LOW;
  HAL_GPIO_Init(GPIOE, &GPIO_InitStruct);

  /*Configure GPIO pins : LB_FR_Pin LB_BRK_Pin */
  GPIO_InitStruct.Pin = LB_FR_Pin|LB_BRK_Pin;
  GPIO_InitStruct.Mode = GPIO_MODE_OUTPUT_PP;
  GPIO_InitStruct.Pull = GPIO_NOPULL;
  GPIO_InitStruct.Speed = GPIO_SPEED_FREQ_LOW;
  HAL_GPIO_Init(GPIOC, &GPIO_InitStruct);

  /*Configure GPIO pins : BS_RST_Pin LD5_Pin LD4_Pin LD3_Pin */
  GPIO_InitStruct.Pin = BS_RST_Pin|LD5_Pin|LD4_Pin|LD3_Pin;
  GPIO_InitStruct.Mode = GPIO_MODE_OUTPUT_PP;
  GPIO_InitStruct.Pull = GPIO_NOPULL;
  GPIO_InitStruct.Speed = GPIO_SPEED_FREQ_LOW;
  HAL_GPIO_Init(GPIOF, &GPIO_InitStruct);

  /*Configure GPIO pin : BS_IRQ_Pin */
  GPIO_InitStruct.Pin = BS_IRQ_Pin;
  GPIO_InitStruct.Mode = GPIO_MODE_IT_RISING_FALLING;
  GPIO_InitStruct.Pull = GPIO_NOPULL;
  HAL_GPIO_Init(BS_IRQ_GPIO_Port, &GPIO_InitStruct);

  /*Configure GPIO pins : FT0_Pin FT1_Pin FT2_Pin FT3_Pin */
  GPIO_InitStruct.Pin = FT0_Pin|FT1_Pin|FT2_Pin|FT3_Pin;
  GPIO_InitStruct.Mode = GPIO_MODE_INPUT;
  GPIO_InitStruct.Pull = GPIO_NOPULL;
  HAL_GPIO_Init(GPIOA, &GPIO_InitStruct);

  /*Configure GPIO pins : ID0_Pin ID1_Pin */
  GPIO_InitStruct.Pin = ID0_Pin|ID1_Pin;
  GPIO_InitStruct.Mode = GPIO_MODE_INPUT;
  GPIO_InitStruct.Pull = GPIO_NOPULL;
  HAL_GPIO_Init(GPIOC, &GPIO_InitStruct);

  /*Configure GPIO pins : ID2_Pin ID3_Pin SPI4_BUSY_Pin */
  GPIO_InitStruct.Pin = ID2_Pin|ID3_Pin|SPI4_BUSY_Pin;
  GPIO_InitStruct.Mode = GPIO_MODE_INPUT;
  GPIO_InitStruct.Pull = GPIO_NOPULL;
  HAL_GPIO_Init(GPIOB, &GPIO_InitStruct);

  /*Configure GPIO pins : LD6_Pin Batt_kill_Pin Charge_Pin */
  GPIO_InitStruct.Pin = LD6_Pin|Batt_kill_Pin|Charge_Pin;
  GPIO_InitStruct.Mode = GPIO_MODE_OUTPUT_PP;
  GPIO_InitStruct.Pull = GPIO_NOPULL;
  GPIO_InitStruct.Speed = GPIO_SPEED_FREQ_LOW;
  HAL_GPIO_Init(GPIOB, &GPIO_InitStruct);

  /*Configure GPIO pins : LD2_Pin LD1_Pin RB_BRK_Pin RB_FR_Pin */
  GPIO_InitStruct.Pin = LD2_Pin|LD1_Pin|RB_BRK_Pin|RB_FR_Pin;
  GPIO_InitStruct.Mode = GPIO_MODE_OUTPUT_PP;
  GPIO_InitStruct.Pull = GPIO_NOPULL;
  GPIO_InitStruct.Speed = GPIO_SPEED_FREQ_LOW;
  HAL_GPIO_Init(GPIOG, &GPIO_InitStruct);

  /*Configure GPIO pins : SPI4_IRQ_Pin Batt_SDN_Pin Batt_IRQ_Pin */
  GPIO_InitStruct.Pin = SPI4_IRQ_Pin|Batt_SDN_Pin|Batt_IRQ_Pin;
  GPIO_InitStruct.Mode = GPIO_MODE_IT_RISING;
  GPIO_InitStruct.Pull = GPIO_NOPULL;
  HAL_GPIO_Init(GPIOB, &GPIO_InitStruct);

  /*Configure GPIO pins : RF_FR_Pin RF_BRK_Pin */
  GPIO_InitStruct.Pin = RF_FR_Pin|RF_BRK_Pin;
  GPIO_InitStruct.Mode = GPIO_MODE_OUTPUT_PP;
  GPIO_InitStruct.Pull = GPIO_NOPULL;
  GPIO_InitStruct.Speed = GPIO_SPEED_FREQ_LOW;
  HAL_GPIO_Init(GPIOA, &GPIO_InitStruct);

  /*Configure GPIO pin : SD_MMC1_CD_Pin */
  GPIO_InitStruct.Pin = SD_MMC1_CD_Pin;
  GPIO_InitStruct.Mode = GPIO_MODE_INPUT;
  GPIO_InitStruct.Pull = GPIO_NOPULL;
  HAL_GPIO_Init(SD_MMC1_CD_GPIO_Port, &GPIO_InitStruct);

  /*Configure GPIO pin : XSENS_IRQ_Pin */
  GPIO_InitStruct.Pin = XSENS_IRQ_Pin;
  GPIO_InitStruct.Mode = GPIO_MODE_IT_RISING;
  GPIO_InitStruct.Pull = GPIO_NOPULL;
  HAL_GPIO_Init(XSENS_IRQ_GPIO_Port, &GPIO_InitStruct);

  /*Configure GPIO pin : XSENS_RST_Pin */
  GPIO_InitStruct.Pin = XSENS_RST_Pin;
  GPIO_InitStruct.Mode = GPIO_MODE_OUTPUT_OD;
  GPIO_InitStruct.Pull = GPIO_NOPULL;
  GPIO_InitStruct.Speed = GPIO_SPEED_FREQ_LOW;
  HAL_GPIO_Init(XSENS_RST_GPIO_Port, &GPIO_InitStruct);

  /*Configure GPIO pin : SPI1_NSS_Pin */
  GPIO_InitStruct.Pin = SPI1_NSS_Pin;
  GPIO_InitStruct.Mode = GPIO_MODE_OUTPUT_PP;
  GPIO_InitStruct.Pull = GPIO_NOPULL;
  GPIO_InitStruct.Speed = GPIO_SPEED_FREQ_HIGH;
  HAL_GPIO_Init(SPI1_NSS_GPIO_Port, &GPIO_InitStruct);

  /*Configure GPIO pins : Interface_EN_Pin Interface_ENnegative_Pin */
  GPIO_InitStruct.Pin = Interface_EN_Pin|Interface_ENnegative_Pin;
  GPIO_InitStruct.Mode = GPIO_MODE_OUTPUT_PP;
  GPIO_InitStruct.Pull = GPIO_NOPULL;
  GPIO_InitStruct.Speed = GPIO_SPEED_FREQ_MEDIUM;
  HAL_GPIO_Init(GPIOG, &GPIO_InitStruct);

  /* EXTI interrupt init*/
  HAL_NVIC_SetPriority(EXTI9_5_IRQn, 4, 0);
  HAL_NVIC_EnableIRQ(EXTI9_5_IRQn);

  HAL_NVIC_SetPriority(EXTI15_10_IRQn, 3, 0);
  HAL_NVIC_EnableIRQ(EXTI15_10_IRQn);

}

void Error_Handler(void)
{
}
